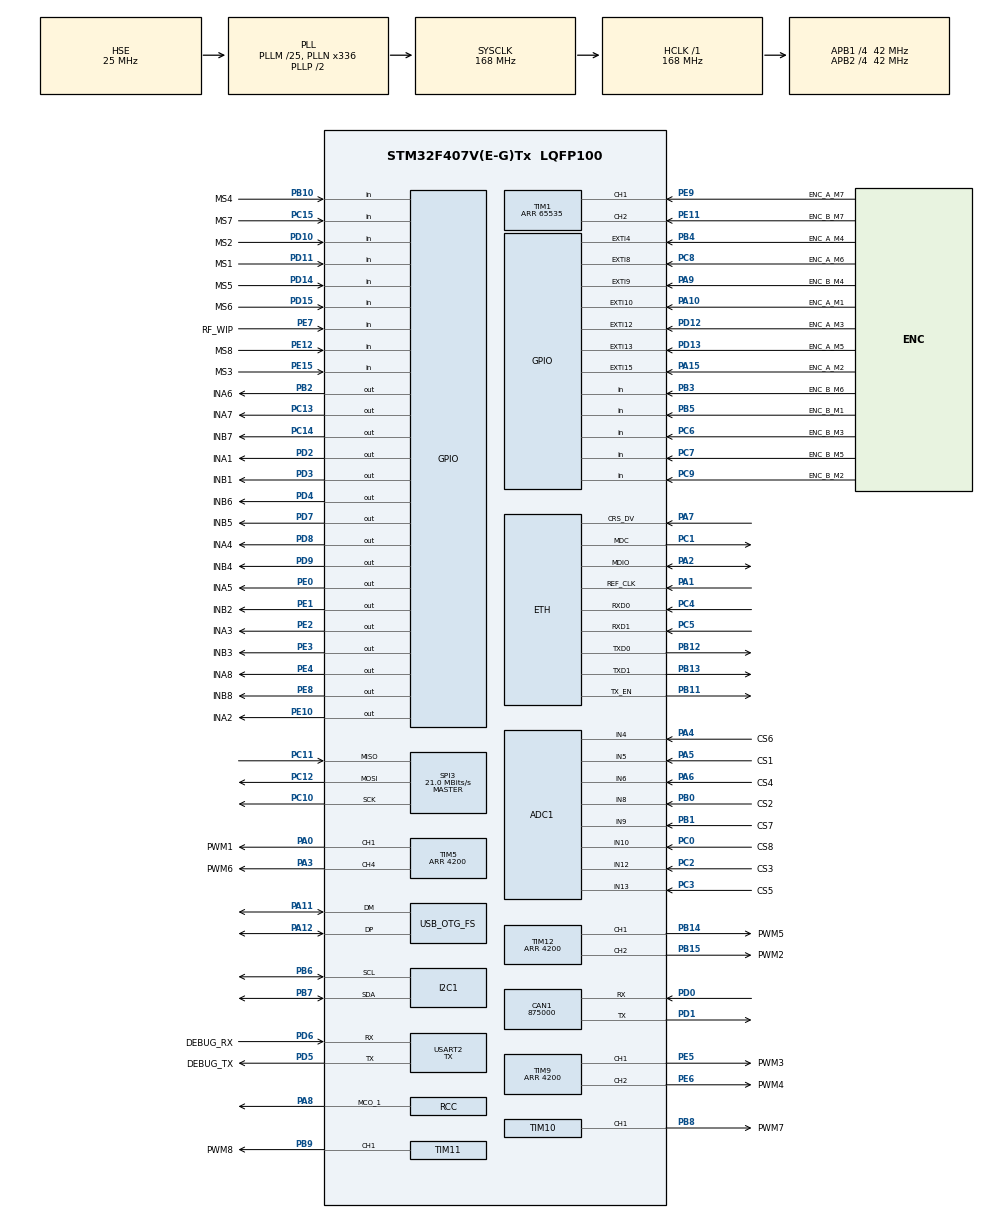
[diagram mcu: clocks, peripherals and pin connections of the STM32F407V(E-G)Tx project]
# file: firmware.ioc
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ADC1.Channel-0\#ChannelRegularConversion=ADC_CHANNEL_4
ADC1.ClockPrescaler=ADC_CLOCK_SYNC_PCLK_DIV4
ADC1.NbrOfConversionFlag=1
ADC1.Rank-0\#ChannelRegularConversion=1
ADC1.SamplingTime-0\#ChannelRegularConversion=ADC_SAMPLETIME_3CYCLES
ADC1.master=1
ADC2.Channel-0\#ChannelRegularConversion=ADC_CHANNEL_4
ADC2.ClockPrescaler=ADC_CLOCK_SYNC_PCLK_DIV4
ADC2.NbrOfConversionFlag=1
ADC2.Rank-0\#ChannelRegularConversion=1
ADC2.SamplingTime-0\#ChannelRegularConversion=ADC_SAMPLETIME_3CYCLES
ADC3.Channel-0\#ChannelRegularConversion=ADC_CHANNEL_10
ADC3.ClockPrescaler=ADC_CLOCK_SYNC_PCLK_DIV4
ADC3.NbrOfConversionFlag=1
ADC3.Rank-0\#ChannelRegularConversion=1
ADC3.SamplingTime-0\#ChannelRegularConversion=ADC_SAMPLETIME_3CYCLES
CAN1.BS1=CAN_BS1_1TQ
CAN1.BS2=CAN_BS2_1TQ
CAN1.CalculateBaudRate=875000
CAN1.CalculateTimeBit=1142
CAN1.CalculateTimeQuantum=380.95238095238096
ETH.ChecksumMode=ETH_CHECKSUM_BY_HARDWARE
ETH.MediaInterface=HAL_ETH_RMII_MODE
ETH.PHY_DUPLEX_STATUS=0x0010
ETH.PHY_Name_RMII=userPHY
ETH.PHY_SPEED_STATUS=0x0004
ETH.PHY_SR=31
ETH.PHY_User_Name=LAN8720A
ETH.PhyAddress=0
FREERTOS.Tasks01=defaultTask,0,256,StartDefaultTask,Default,NULL,Dynamic,NULL,NULL
FREERTOS.configENABLE_FPU=0
FREERTOS.configGENERATE_RUN_TIME_STATS=1
FREERTOS.configTOTAL_HEAP_SIZE=32360
FREERTOS.configUSE_STATS_FORMATTING_FUNCTIONS=1
FREERTOS.configUSE_TRACE_FACILITY=1
LWIP.API_LIB_DEBUG=LWIP_DBG_ON
LWIP.API_MSG_DEBUG=LWIP_DBG_ON
LWIP.BSP.number=1
LWIP.DHCP_DEBUG=LWIP_DBG_ON
LWIP.ETHARP_DEBUG=LWIP_DBG_ON
LWIP.GATEWAY_ADDRESS=010.000.000.001
LWIP.ICMP_DEBUG=LWIP_DBG_ON
LWIP.IGMP_DEBUG=LWIP_DBG_ON
LWIP.INET_DEBUG=LWIP_DBG_ON
LWIP.IP_ADDRESS=010.000.000.002
LWIP.IP_DEBUG=LWIP_DBG_ON
LWIP.IP_REASS_DEBUG=LWIP_DBG_OFF
LWIP.LWIP_DBG_MIN_LEVEL=LWIP_DBG_LEVEL_WARNING
LWIP.LWIP_DHCP=1
LWIP.LWIP_DNS=1
LWIP.LWIP_IGMP=1
LWIP.LWIP_MDNS=1
LWIP.LWIP_MDNS_RESPONDER=1
LWIP.LWIP_RAM_HEAP_POINTER=0x30044000
LWIP.LWIP_SNTP=1
LWIP.MDNS_MAX_SERVICES=2
LWIP.MEMP_MEM_INIT=0
LWIP.MEMP_MEM_MALLOC=0
LWIP.MEMP_NUM_TCP_PCB=10
LWIP.NETIF_DEBUG=LWIP_DBG_ON
LWIP.NETMASK_ADDRESS=255.255.255.000
LWIP.PBUF_DEBUG=LWIP_DBG_ON
LWIP.RAW_DEBUG=LWIP_DBG_ON
LWIP.SOCKETS_DEBUG=LWIP_DBG_ON
LWIP.TCPIP_DEBUG=LWIP_DBG_ON
LWIP.TCP_DEBUG=LWIP_DBG_ON
LWIP.TCP_INPUT_DEBUG=LWIP_DBG_ON
LWIP.Version=v2.1.2_Cube
LWIP0.BSP.STBoard=false
LWIP0.BSP.api=BSP_COMPONENT_DRIVER
LWIP0.BSP.component=LAN8742
LWIP0.BSP.i2caddr=0
LWIP0.BSP.instance=LAN8742
LWIP0.BSP.name=Driver_PHY
LWIP0.BSP.semaphore=S_LAN8742
LWIP0.BSP.solution=LAN8742
MBEDTLS.MBEDTLS_RNG_IP=SW_RNG
Mcu.Family=STM32F4
Mcu.Name=STM32F407V(E-G)Tx
Mcu.Package=LQFP100
NVIC.ETH_IRQn=true\:5\:0\:false\:false\:true\:true\:false\:true\:true
NVIC.EXTI15_10_IRQn=true\:5\:0\:false\:false\:true\:true\:true\:true\:true
NVIC.EXTI4_IRQn=true\:5\:0\:false\:false\:true\:true\:true\:true\:true
NVIC.EXTI9_5_IRQn=true\:5\:0\:false\:false\:true\:true\:true\:true\:true
NVIC.OTG_FS_IRQn=true\:5\:0\:false\:false\:true\:true\:false\:true\:true
NVIC.PriorityGroup=NVIC_PRIORITYGROUP_4
NVIC.TIM6_DAC_IRQn=true\:5\:0\:false\:false\:true\:true\:true\:true\:true
PA0-WKUP.GPIO_Label=PWM1
PA0-WKUP.Signal=S_TIM5_CH1
PA1.Mode=RMII
PA1.Signal=ETH_REF_CLK
PA10.GPIO_Label=ENC_A_M1
PA10.GPIO_ModeDefaultEXTI=GPIO_MODE_IT_RISING_FALLING
PA10.GPIO_PuPd=GPIO_PULLUP
PA10.Signal=GPXTI10
PA11.Mode=Device_Only
PA11.Signal=USB_OTG_FS_DM
PA12.Mode=Device_Only
PA12.Signal=USB_OTG_FS_DP
PA13.Mode=Serial_Wire
PA13.Signal=SYS_JTMS-SWDIO
PA14.Mode=Serial_Wire
PA14.Signal=SYS_JTCK-SWCLK
PA15.GPIO_Label=ENC_A_M2
PA15.GPIO_ModeDefaultEXTI=GPIO_MODE_IT_RISING_FALLING
PA15.GPIO_PuPd=GPIO_PULLUP
PA15.Signal=GPXTI15
PA2.Mode=RMII
PA2.Signal=ETH_MDIO
PA3.GPIO_Label=PWM6
PA3.Signal=S_TIM5_CH4
PA4.GPIO_Label=CS6
PA4.Signal=ADCx_IN4
PA5.GPIO_Label=CS1
PA5.Signal=ADCx_IN5
PA6.GPIO_Label=CS4
PA6.Signal=ADCx_IN6
PA7.Mode=RMII
PA7.Signal=ETH_CRS_DV
PA8.Mode=Clock-out-1
PA8.Signal=RCC_MCO_1
PA9.GPIO_Label=ENC_B_M4
PA9.GPIO_ModeDefaultEXTI=GPIO_MODE_IT_RISING_FALLING
PA9.GPIO_PuPd=GPIO_PULLUP
PA9.Signal=GPXTI9
PB0.GPIO_Label=CS2
PB0.Signal=ADCx_IN8
PB1.GPIO_Label=CS7
PB1.Signal=ADCx_IN9
PB10.GPIO_Label=MS4
PB10.GPIO_PuPd=GPIO_PULLUP
PB10.Signal=GPIO_Input
PB11.Mode=RMII
PB11.Signal=ETH_TX_EN
PB12.Mode=RMII
PB12.Signal=ETH_TXD0
PB13.Mode=RMII
PB13.Signal=ETH_TXD1
PB14.GPIO_Label=PWM5
PB14.Signal=S_TIM12_CH1
PB15.GPIO_Label=PWM2
PB15.Signal=S_TIM12_CH2
PB2.GPIO_Label=INA6
PB2.Signal=GPIO_Output
PB3.GPIO_Label=ENC_B_M6
PB3.GPIO_PuPd=GPIO_PULLUP
PB3.Signal=GPIO_Input
PB4.GPIO_Label=ENC_A_M4
PB4.GPIO_ModeDefaultEXTI=GPIO_MODE_IT_RISING_FALLING
PB4.GPIO_PuPd=GPIO_PULLUP
PB4.Signal=GPXTI4
PB5.GPIO_Label=ENC_B_M1
PB5.GPIO_PuPd=GPIO_PULLUP
PB5.Signal=GPIO_Input
PB6.GPIO_Pu=GPIO_PULLUP
PB6.Mode=I2C
PB6.Signal=I2C1_SCL
PB7.GPIO_Pu=GPIO_PULLUP
PB7.Mode=I2C
PB7.Signal=I2C1_SDA
PB8.GPIO_Label=PWM7
PB8.Signal=S_TIM10_CH1
PB9.GPIO_Label=PWM8
PB9.Signal=S_TIM11_CH1
PC0.GPIO_Label=CS8
PC0.Signal=ADCx_IN10
PC1.Mode=RMII
PC1.Signal=ETH_MDC
PC10.Mode=Full_Duplex_Master
PC10.Signal=SPI3_SCK
PC11.Mode=Full_Duplex_Master
PC11.Signal=SPI3_MISO
PC12.Mode=Full_Duplex_Master
PC12.Signal=SPI3_MOSI
PC13-ANTI_TAMP.GPIO_Label=INA7
PC13-ANTI_TAMP.Signal=GPIO_Output
PC14-OSC32_IN.GPIO_Label=INB7
PC14-OSC32_IN.Signal=GPIO_Output
PC15-OSC32_OUT.GPIO_Label=MS7
PC15-OSC32_OUT.GPIO_PuPd=GPIO_PULLUP
PC15-OSC32_OUT.Signal=GPIO_Input
PC2.GPIO_Label=CS3
PC2.Signal=ADCx_IN12
PC3.GPIO_Label=CS5
PC3.Signal=ADCx_IN13
PC4.Mode=RMII
PC4.Signal=ETH_RXD0
PC5.Mode=RMII
PC5.Signal=ETH_RXD1
PC6.GPIO_Label=ENC_B_M3
PC6.GPIO_PuPd=GPIO_PULLUP
PC6.Signal=GPIO_Input
PC7.GPIO_Label=ENC_B_M5
PC7.GPIO_PuPd=GPIO_PULLUP
PC7.Signal=GPIO_Input
PC8.GPIO_Label=ENC_A_M6
PC8.GPIO_ModeDefaultEXTI=GPIO_MODE_IT_RISING_FALLING
PC8.GPIO_PuPd=GPIO_PULLUP
PC8.Signal=GPXTI8
PC9.GPIO_Label=ENC_B_M2
PC9.GPIO_PuPd=GPIO_PULLUP
PC9.Signal=GPIO_Input
PD0.Mode=CAN_Activate
PD0.Signal=CAN1_RX
PD1.Mode=CAN_Activate
PD1.Signal=CAN1_TX
PD10.GPIO_Label=MS2
PD10.GPIO_PuPd=GPIO_PULLUP
PD10.Signal=GPIO_Input
PD11.GPIO_Label=MS1
PD11.GPIO_PuPd=GPIO_PULLUP
PD11.Signal=GPIO_Input
PD12.GPIO_Label=ENC_A_M3
PD12.GPIO_ModeDefaultEXTI=GPIO_MODE_IT_RISING_FALLING
PD12.GPIO_PuPd=GPIO_PULLUP
PD12.Signal=GPXTI12
PD13.GPIO_Label=ENC_A_M5
PD13.GPIO_ModeDefaultEXTI=GPIO_MODE_IT_RISING_FALLING
PD13.GPIO_PuPd=GPIO_PULLUP
PD13.Signal=GPXTI13
PD14.GPIO_Label=MS5
PD14.GPIO_PuPd=GPIO_PULLUP
PD14.Signal=GPIO_Input
PD15.GPIO_Label=MS6
PD15.GPIO_PuPd=GPIO_PULLUP
PD15.Signal=GPIO_Input
PD2.GPIO_Label=INA1
PD2.Signal=GPIO_Output
PD3.GPIO_Label=INB1
PD3.Signal=GPIO_Output
PD4.GPIO_Label=INB6
PD4.Signal=GPIO_Output
PD5.GPIO_Label=DEBUG_TX
PD5.Mode=Asynchronous
PD5.Signal=USART2_TX
PD6.GPIO_Label=DEBUG_RX
PD6.Mode=Asynchronous
PD6.Signal=USART2_RX
PD7.GPIO_Label=INB5
PD7.Signal=GPIO_Output
PD8.GPIO_Label=INA4
PD8.Signal=GPIO_Output
PD9.GPIO_Label=INB4
PD9.Signal=GPIO_Output
PE0.GPIO_Label=INA5
PE0.Signal=GPIO_Output
PE1.GPIO_Label=INB2
PE1.Signal=GPIO_Output
PE10.GPIO_Label=INA2
PE10.Signal=GPIO_Output
PE11.GPIO_Label=ENC_B_M7
PE11.Signal=S_TIM1_CH2
PE12.GPIO_Label=MS8
PE12.GPIO_PuPd=GPIO_PULLUP
PE12.Signal=GPIO_Input
PE15.GPIO_Label=MS3
PE15.GPIO_PuPd=GPIO_PULLUP
PE15.Signal=GPIO_Input
PE2.GPIO_Label=INA3
PE2.Signal=GPIO_Output
PE3.GPIO_Label=INB3
PE3.Signal=GPIO_Output
PE4.GPIO_Label=INA8
PE4.Signal=GPIO_Output
PE5.GPIO_Label=PWM3
PE5.Signal=S_TIM9_CH1
PE6.GPIO_Label=PWM4
PE6.Signal=S_TIM9_CH2
PE7.GPIO_Label=RF_WIP
PE7.Signal=GPIO_Input
PE8.GPIO_Label=INB8
PE8.Signal=GPIO_Output
PE9.GPIO_Label=ENC_A_M7
PE9.Signal=S_TIM1_CH1
PH0-OSC_IN.Mode=HSE-External-Oscillator
PH0-OSC_IN.Signal=RCC_OSC_IN
PH1-OSC_OUT.Mode=HSE-External-Oscillator
PH1-OSC_OUT.Signal=RCC_OSC_OUT
ProjectManager.HeapSize=0x400
ProjectManager.StackSize=0x600
ProjectManager.TargetToolchain=Makefile
RCC.48MHZClocksFreq_Value=48000000
RCC.AHBFreq_Value=168000000
RCC.APB1CLKDivider=RCC_HCLK_DIV4
RCC.APB1Freq_Value=42000000
RCC.APB1TimFreq_Value=84000000
RCC.APB2CLKDivider=RCC_HCLK_DIV4
RCC.APB2Freq_Value=42000000
RCC.APB2TimFreq_Value=84000000
RCC.CortexFreq_Value=168000000
RCC.HCLKFreq_Value=168000000
RCC.HSE_VALUE=25000000
RCC.HSI_VALUE=16000000
RCC.LSE_VALUE=32768
RCC.PLLM=25
RCC.PLLN=336
RCC.PLLQ=7
RCC.RCC_MCO1Source=RCC_MCO1SOURCE_HSE
RCC.SYSCLKFreq_VALUE=168000000
RCC.SYSCLKSource=RCC_SYSCLKSOURCE_PLLCLK
RCC.VCOOutputFreq_Value=336000000
SH.ADCx_IN10.0=ADC1_IN10,IN10
SH.ADCx_IN10.1=ADC2_IN10,IN10
SH.ADCx_IN10.2=ADC3_IN10,IN10
SH.ADCx_IN12.0=ADC1_IN12,IN12
SH.ADCx_IN12.1=ADC2_IN12,IN12
SH.ADCx_IN12.2=ADC3_IN12,IN12
SH.ADCx_IN13.0=ADC1_IN13,IN13
SH.ADCx_IN13.1=ADC2_IN13,IN13
SH.ADCx_IN13.2=ADC3_IN13,IN13
SH.ADCx_IN4.0=ADC1_IN4,IN4
SH.ADCx_IN4.1=ADC2_IN4,IN4
SH.ADCx_IN5.0=ADC1_IN5,IN5
SH.ADCx_IN5.1=ADC2_IN5,IN5
SH.ADCx_IN6.0=ADC1_IN6,IN6
SH.ADCx_IN6.1=ADC2_IN6,IN6
SH.ADCx_IN8.0=ADC1_IN8,IN8
SH.ADCx_IN8.1=ADC2_IN8,IN8
SH.ADCx_IN9.0=ADC1_IN9,IN9
SH.ADCx_IN9.1=ADC2_IN9,IN9
SH.S_TIM10_CH1.0=TIM10_CH1,PWM Generation1 CH1
SH.S_TIM11_CH1.0=TIM11_CH1,PWM Generation1 CH1
SH.S_TIM12_CH1.0=TIM12_CH1,PWM Generation1 CH1
SH.S_TIM12_CH2.0=TIM12_CH2,PWM Generation2 CH2
SH.S_TIM1_CH1.0=TIM1_CH1,Encoder_Interface
SH.S_TIM1_CH2.0=TIM1_CH2,Encoder_Interface
SH.S_TIM5_CH1.0=TIM5_CH1,PWM Generation1 CH1
SH.S_TIM5_CH4.0=TIM5_CH4,PWM Generation4 CH4
SH.S_TIM9_CH1.0=TIM9_CH1,PWM Generation1 CH1
SH.S_TIM9_CH2.0=TIM9_CH2,PWM Generation2 CH2
SPI3.BaudRatePrescaler=SPI_BAUDRATEPRESCALER_2
SPI3.CalculateBaudRate=21.0 MBits/s
SPI3.Direction=SPI_DIRECTION_2LINES
SPI3.Mode=SPI_MODE_MASTER
SPI3.VirtualType=VM_MASTER
TIM1.Period=65535
TIM10.Channel=TIM_CHANNEL_1
TIM10.Period=4200
TIM10.Prescaler=0
TIM10.Pulse=0
TIM11.Channel=TIM_CHANNEL_1
TIM11.Period=4200
TIM12.Channel-PWM\ Generation1\ CH1=TIM_CHANNEL_1
TIM12.Channel-PWM\ Generation2\ CH2=TIM_CHANNEL_2
TIM12.Period=4200
TIM5.Channel-PWM\ Generation1\ CH1=TIM_CHANNEL_1
TIM5.Channel-PWM\ Generation4\ CH4=TIM_CHANNEL_4
TIM5.Period=4200
TIM6.Period=1
TIM6.Prescaler=8399
TIM6.TIM_MasterOutputTrigger=TIM_TRGO_UPDATE
TIM9.Channel-PWM\ Generation1\ CH1=TIM_CHANNEL_1
TIM9.Channel-PWM\ Generation2\ CH2=TIM_CHANNEL_2
TIM9.Period=4200
USART2.Mode=MODE_TX
USART2.VirtualMode=VM_ASYNC
USB_DEVICE.CLASS_NAME_FS=HID
USB_DEVICE.VirtualMode-HID_FS=Hid
USB_DEVICE.VirtualModeFS=Hid_FS
USB_OTG_FS.VirtualMode=Device_Only
VP_FREERTOS_VS_CMSIS_V1.Mode=CMSIS_V1
VP_LWIP_VS_Enabled.Mode=Enabled
VP_MBEDTLS_VS_MBEDTLS.Mode=Enabled
VP_TIM10_VS_ClockSourceINT.Mode=Enable_Timer
VP_TIM11_VS_ClockSourceINT.Mode=Enable_Timer
VP_TIM6_VS_ClockSourceINT.Mode=Enable_Timer
VP_USB_DEVICE_VS_USB_DEVICE_HID_FS.Mode=HID_FS
board=firmware

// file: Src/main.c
/* USER CODE BEGIN Header */
/**
  ******************************************************************************
  * @file           : main.c
  * @brief          : Main program body
  ******************************************************************************
  * @attention
  *
  * Copyright (c) 2025 STMicroelectronics.
  * All rights reserved.
  *
  * This software is licensed under terms that can be found in the LICENSE file
  * in the root directory of this software component.
  * If no LICENSE file comes with this software, it is provided AS-IS.
  *
  ******************************************************************************
  */
/* USER CODE END Header */
#include "main.h"
#include "cmsis_os.h"
#include "mbedtls.h"
#include "usb_device.h"

/* USER CODE BEGIN Includes */
#include "lwip.h"
#include "scorbot.h"
#include "motor.h"

/* USER CODE END Includes */

 ADC_HandleTypeDef hadc1;
ADC_HandleTypeDef hadc2;
ADC_HandleTypeDef hadc3;

CAN_HandleTypeDef hcan1;

I2C_HandleTypeDef hi2c1;

SPI_HandleTypeDef hspi3;

TIM_HandleTypeDef htim1;
TIM_HandleTypeDef htim5;
TIM_HandleTypeDef htim6;
TIM_HandleTypeDef htim9;
TIM_HandleTypeDef htim10;
TIM_HandleTypeDef htim11;
TIM_HandleTypeDef htim12;

UART_HandleTypeDef huart2;

osThreadId defaultTaskHandle;
/* USER CODE BEGIN PV */
/* Private variables ---------------------------------------------------------*/

/* USER CODE END PV */

void SystemClock_Config(void);
static void MX_GPIO_Init(void);
static void MX_ADC1_Init(void);
static void MX_ADC2_Init(void);
static void MX_ADC3_Init(void);
static void MX_CAN1_Init(void);
static void MX_I2C1_Init(void);
static void MX_SPI3_Init(void);
static void MX_TIM1_Init(void);
static void MX_TIM5_Init(void);
static void MX_TIM6_Init(void);
static void MX_TIM9_Init(void);
static void MX_TIM10_Init(void);
static void MX_TIM11_Init(void);
static void MX_TIM12_Init(void);
static void MX_USART2_UART_Init(void);
void StartDefaultTask(void const * argument);

/* USER CODE BEGIN PFP */
/* Private function prototypes -----------------------------------------------*/

/* USER CODE END PFP */

/* USER CODE BEGIN 0 */
#define DHCP_START                 1
#define DHCP_WAIT_ADDRESS          2
#define DHCP_ADDRESS_ASSIGNED      3
#define DHCP_TIMEOUT               4
#define DHCP_LINK_DOWN             5

#define DHCP_TASK_PRIO   ( tskIDLE_PRIORITY + 4 )

uint8_t DHCP_state;

/* Retarget printf to UART2 */
int _write(int file, char *ptr, int len)
{
    HAL_UART_Transmit(&huart2, (uint8_t *)ptr, len, HAL_MAX_DELAY);
    return len;
}
/* USER CODE END 0 */

int main(void)
{

  /* MCU Configuration--------------------------------------------------------*/

  /* Reset of all peripherals, Initializes the Flash interface and the Systick. */
  HAL_Init();

  /* Configure the system clock */
  SystemClock_Config();

  /* USER CODE BEGIN SysInit */
  __HAL_RCC_GPIOB_CLK_ENABLE();

  /*Configure GPIO pin Output Level */
  HAL_GPIO_WritePin(GPIOB, GPIO_PIN_6, 0);

  GPIO_InitTypeDef GPIO_InitStruct;

  GPIO_InitStruct.Pin = GPIO_PIN_6;
  GPIO_InitStruct.Mode = GPIO_MODE_OUTPUT_PP;
  GPIO_InitStruct.Pull = GPIO_NOPULL;
  GPIO_InitStruct.Speed = GPIO_SPEED_FREQ_LOW;
  HAL_GPIO_Init(GPIOB, &GPIO_InitStruct);
  HAL_Delay(1);
  HAL_GPIO_WritePin(GPIOB, GPIO_PIN_6, 1);
  HAL_Delay(1);
  /* USER CODE END SysInit */

  /* Initialize all configured peripherals */
  MX_GPIO_Init();
  MX_ADC1_Init();
  MX_ADC2_Init();
  MX_ADC3_Init();
  MX_CAN1_Init();
  MX_I2C1_Init();
  MX_SPI3_Init();
  MX_TIM1_Init();
  MX_TIM5_Init();
  MX_TIM6_Init();
  MX_TIM9_Init();
  MX_TIM10_Init();
  MX_TIM11_Init();
  MX_TIM12_Init();
  MX_USART2_UART_Init();
  MX_MBEDTLS_Init();
  /* USER CODE BEGIN 2 */
  printf("Starting...\r\n");
  motor_init();

//  TIM10->ARR = 12000;
//  HAL_TIM_Base_Start_IT(&htim6); // motor interrupt loop
//  INA7_GPIO_Port->ODR |= INA7_Pin;
//  TIM10->CCR1 = 0xffff;

  /* USER CODE END 2 */

  /* Create the thread(s) */
  /* definition and creation of defaultTask */
  osThreadDef(defaultTask, StartDefaultTask, osPriorityNormal, 0, 256);
  defaultTaskHandle = osThreadCreate(osThread(defaultTask), NULL);

  /* Start scheduler */
  osKernelStart();

  /* We should never get here as control is now taken by the scheduler */
  /* Infinite loop */
  while (1)
  {

  }
}

void SystemClock_Config(void)
{
  RCC_OscInitTypeDef RCC_OscInitStruct = {0};
  RCC_ClkInitTypeDef RCC_ClkInitStruct = {0};

  /** Configure the main internal regulator output voltage
  */
  __HAL_RCC_PWR_CLK_ENABLE();
  __HAL_PWR_VOLTAGESCALING_CONFIG(PWR_REGULATOR_VOLTAGE_SCALE1);

  /** Initializes the RCC Oscillators according to the specified parameters
  * in the RCC_OscInitTypeDef structure.
  */
  RCC_OscInitStruct.OscillatorType = RCC_OSCILLATORTYPE_HSE;
  RCC_OscInitStruct.HSEState = RCC_HSE_ON;
  RCC_OscInitStruct.PLL.PLLState = RCC_PLL_ON;
  RCC_OscInitStruct.PLL.PLLSource = RCC_PLLSOURCE_HSE;
  RCC_OscInitStruct.PLL.PLLM = 25;
  RCC_OscInitStruct.PLL.PLLN = 336;
  RCC_OscInitStruct.PLL.PLLP = RCC_PLLP_DIV2;
  RCC_OscInitStruct.PLL.PLLQ = 7;
  if (HAL_RCC_OscConfig(&RCC_OscInitStruct) != HAL_OK)
  {
    Error_Handler();
  }

  /** Initializes the CPU, AHB and APB buses clocks
  */
  RCC_ClkInitStruct.ClockType = RCC_CLOCKTYPE_HCLK|RCC_CLOCKTYPE_SYSCLK
                              |RCC_CLOCKTYPE_PCLK1|RCC_CLOCKTYPE_PCLK2;
  RCC_ClkInitStruct.SYSCLKSource = RCC_SYSCLKSOURCE_PLLCLK;
  RCC_ClkInitStruct.AHBCLKDivider = RCC_SYSCLK_DIV1;
  RCC_ClkInitStruct.APB1CLKDivider = RCC_HCLK_DIV4;
  RCC_ClkInitStruct.APB2CLKDivider = RCC_HCLK_DIV4;

  if (HAL_RCC_ClockConfig(&RCC_ClkInitStruct, FLASH_LATENCY_5) != HAL_OK)
  {
    Error_Handler();
  }
  HAL_RCC_MCOConfig(RCC_MCO1, RCC_MCO1SOURCE_HSE, RCC_MCODIV_1);
}

static void MX_ADC1_Init(void)
{

  ADC_ChannelConfTypeDef sConfig = {0};

  /** Configure the global features of the ADC (Clock, Resolution, Data Alignment and number of conversion)
  */
  hadc1.Instance = ADC1;
  hadc1.Init.ClockPrescaler = ADC_CLOCK_SYNC_PCLK_DIV4;
  hadc1.Init.Resolution = ADC_RESOLUTION_12B;
  hadc1.Init.ScanConvMode = DISABLE;
  hadc1.Init.ContinuousConvMode = DISABLE;
  hadc1.Init.DiscontinuousConvMode = DISABLE;
  hadc1.Init.ExternalTrigConvEdge = ADC_EXTERNALTRIGCONVEDGE_NONE;
  hadc1.Init.ExternalTrigConv = ADC_SOFTWARE_START;
  hadc1.Init.DataAlign = ADC_DATAALIGN_RIGHT;
  hadc1.Init.NbrOfConversion = 1;
  hadc1.Init.DMAContinuousRequests = DISABLE;
  hadc1.Init.EOCSelection = ADC_EOC_SINGLE_CONV;
  if (HAL_ADC_Init(&hadc1) != HAL_OK)
  {
    Error_Handler();
  }

  /** Configure for the selected ADC regular channel its corresponding rank in the sequencer and its sample time.
  */
  sConfig.Channel = ADC_CHANNEL_4;
  sConfig.Rank = 1;
  sConfig.SamplingTime = ADC_SAMPLETIME_3CYCLES;
  if (HAL_ADC_ConfigChannel(&hadc1, &sConfig) != HAL_OK)
  {
    Error_Handler();
  }

}

static void MX_ADC2_Init(void)
{

  ADC_ChannelConfTypeDef sConfig = {0};

  /** Configure the global features of the ADC (Clock, Resolution, Data Alignment and number of conversion)
  */
  hadc2.Instance = ADC2;
  hadc2.Init.ClockPrescaler = ADC_CLOCK_SYNC_PCLK_DIV4;
  hadc2.Init.Resolution = ADC_RESOLUTION_12B;
  hadc2.Init.ScanConvMode = DISABLE;
  hadc2.Init.ContinuousConvMode = DISABLE;
  hadc2.Init.DiscontinuousConvMode = DISABLE;
  hadc2.Init.ExternalTrigConvEdge = ADC_EXTERNALTRIGCONVEDGE_NONE;
  hadc2.Init.ExternalTrigConv = ADC_SOFTWARE_START;
  hadc2.Init.DataAlign = ADC_DATAALIGN_RIGHT;
  hadc2.Init.NbrOfConversion = 1;
  hadc2.Init.DMAContinuousRequests = DISABLE;
  hadc2.Init.EOCSelection = ADC_EOC_SINGLE_CONV;
  if (HAL_ADC_Init(&hadc2) != HAL_OK)
  {
    Error_Handler();
  }

  /** Configure for the selected ADC regular channel its corresponding rank in the sequencer and its sample time.
  */
  sConfig.Channel = ADC_CHANNEL_4;
  sConfig.Rank = 1;
  sConfig.SamplingTime = ADC_SAMPLETIME_3CYCLES;
  if (HAL_ADC_ConfigChannel(&hadc2, &sConfig) != HAL_OK)
  {
    Error_Handler();
  }

}

static void MX_ADC3_Init(void)
{

  ADC_ChannelConfTypeDef sConfig = {0};

  /** Configure the global features of the ADC (Clock, Resolution, Data Alignment and number of conversion)
  */
  hadc3.Instance = ADC3;
  hadc3.Init.ClockPrescaler = ADC_CLOCK_SYNC_PCLK_DIV4;
  hadc3.Init.Resolution = ADC_RESOLUTION_12B;
  hadc3.Init.ScanConvMode = DISABLE;
  hadc3.Init.ContinuousConvMode = DISABLE;
  hadc3.Init.DiscontinuousConvMode = DISABLE;
  hadc3.Init.ExternalTrigConvEdge = ADC_EXTERNALTRIGCONVEDGE_NONE;
  hadc3.Init.ExternalTrigConv = ADC_SOFTWARE_START;
  hadc3.Init.DataAlign = ADC_DATAALIGN_RIGHT;
  hadc3.Init.NbrOfConversion = 1;
  hadc3.Init.DMAContinuousRequests = DISABLE;
  hadc3.Init.EOCSelection = ADC_EOC_SINGLE_CONV;
  if (HAL_ADC_Init(&hadc3) != HAL_OK)
  {
    Error_Handler();
  }

  /** Configure for the selected ADC regular channel its corresponding rank in the sequencer and its sample time.
  */
  sConfig.Channel = ADC_CHANNEL_10;
  sConfig.Rank = 1;
  sConfig.SamplingTime = ADC_SAMPLETIME_3CYCLES;
  if (HAL_ADC_ConfigChannel(&hadc3, &sConfig) != HAL_OK)
  {
    Error_Handler();
  }

}

static void MX_CAN1_Init(void)
{

  hcan1.Instance = CAN1;
  hcan1.Init.Prescaler = 16;
  hcan1.Init.Mode = CAN_MODE_NORMAL;
  hcan1.Init.SyncJumpWidth = CAN_SJW_1TQ;
  hcan1.Init.TimeSeg1 = CAN_BS1_1TQ;
  hcan1.Init.TimeSeg2 = CAN_BS2_1TQ;
  hcan1.Init.TimeTriggeredMode = DISABLE;
  hcan1.Init.AutoBusOff = DISABLE;
  hcan1.Init.AutoWakeUp = DISABLE;
  hcan1.Init.AutoRetransmission = DISABLE;
  hcan1.Init.ReceiveFifoLocked = DISABLE;
  hcan1.Init.TransmitFifoPriority = DISABLE;
  if (HAL_CAN_Init(&hcan1) != HAL_OK)
  {
    Error_Handler();
  }

}

static void MX_I2C1_Init(void)
{

  hi2c1.Instance = I2C1;
  hi2c1.Init.ClockSpeed = 100000;
  hi2c1.Init.DutyCycle = I2C_DUTYCYCLE_2;
  hi2c1.Init.OwnAddress1 = 0;
  hi2c1.Init.AddressingMode = I2C_ADDRESSINGMODE_7BIT;
  hi2c1.Init.DualAddressMode = I2C_DUALADDRESS_DISABLE;
  hi2c1.Init.OwnAddress2 = 0;
  hi2c1.Init.GeneralCallMode = I2C_GENERALCALL_DISABLE;
  hi2c1.Init.NoStretchMode = I2C_NOSTRETCH_DISABLE;
  if (HAL_I2C_Init(&hi2c1) != HAL_OK)
  {
    Error_Handler();
  }

}

static void MX_SPI3_Init(void)
{

  /* SPI3 parameter configuration*/
  hspi3.Instance = SPI3;
  hspi3.Init.Mode = SPI_MODE_MASTER;
  hspi3.Init.Direction = SPI_DIRECTION_2LINES;
  hspi3.Init.DataSize = SPI_DATASIZE_8BIT;
  hspi3.Init.CLKPolarity = SPI_POLARITY_LOW;
  hspi3.Init.CLKPhase = SPI_PHASE_1EDGE;
  hspi3.Init.NSS = SPI_NSS_SOFT;
  hspi3.Init.BaudRatePrescaler = SPI_BAUDRATEPRESCALER_2;
  hspi3.Init.FirstBit = SPI_FIRSTBIT_MSB;
  hspi3.Init.TIMode = SPI_TIMODE_DISABLE;
  hspi3.Init.CRCCalculation = SPI_CRCCALCULATION_DISABLE;
  hspi3.Init.CRCPolynomial = 10;
  if (HAL_SPI_Init(&hspi3) != HAL_OK)
  {
    Error_Handler();
  }

}

static void MX_TIM1_Init(void)
{

  TIM_Encoder_InitTypeDef sConfig = {0};
  TIM_MasterConfigTypeDef sMasterConfig = {0};

  htim1.Instance = TIM1;
  htim1.Init.Prescaler = 0;
  htim1.Init.CounterMode = TIM_COUNTERMODE_UP;
  htim1.Init.Period = 65535;
  htim1.Init.ClockDivision = TIM_CLOCKDIVISION_DIV1;
  htim1.Init.RepetitionCounter = 0;
  htim1.Init.AutoReloadPreload = TIM_AUTORELOAD_PRELOAD_DISABLE;
  sConfig.EncoderMode = TIM_ENCODERMODE_TI1;
  sConfig.IC1Polarity = TIM_ICPOLARITY_RISING;
  sConfig.IC1Selection = TIM_ICSELECTION_DIRECTTI;
  sConfig.IC1Prescaler = TIM_ICPSC_DIV1;
  sConfig.IC1Filter = 0;
  sConfig.IC2Polarity = TIM_ICPOLARITY_RISING;
  sConfig.IC2Selection = TIM_ICSELECTION_DIRECTTI;
  sConfig.IC2Prescaler = TIM_ICPSC_DIV1;
  sConfig.IC2Filter = 0;
  if (HAL_TIM_Encoder_Init(&htim1, &sConfig) != HAL_OK)
  {
    Error_Handler();
  }
  sMasterConfig.MasterOutputTrigger = TIM_TRGO_RESET;
  sMasterConfig.MasterSlaveMode = TIM_MASTERSLAVEMODE_DISABLE;
  if (HAL_TIMEx_MasterConfigSynchronization(&htim1, &sMasterConfig) != HAL_OK)
  {
    Error_Handler();
  }

}

static void MX_TIM5_Init(void)
{

  TIM_MasterConfigTypeDef sMasterConfig = {0};
  TIM_OC_InitTypeDef sConfigOC = {0};

  htim5.Instance = TIM5;
  htim5.Init.Prescaler = 0;
  htim5.Init.CounterMode = TIM_COUNTERMODE_UP;
  htim5.Init.Period = 4200;
  htim5.Init.ClockDivision = TIM_CLOCKDIVISION_DIV1;
  htim5.Init.AutoReloadPreload = TIM_AUTORELOAD_PRELOAD_DISABLE;
  if (HAL_TIM_PWM_Init(&htim5) != HAL_OK)
  {
    Error_Handler();
  }
  sMasterConfig.MasterOutputTrigger = TIM_TRGO_RESET;
  sMasterConfig.MasterSlaveMode = TIM_MASTERSLAVEMODE_DISABLE;
  if (HAL_TIMEx_MasterConfigSynchronization(&htim5, &sMasterConfig) != HAL_OK)
  {
    Error_Handler();
  }
  sConfigOC.OCMode = TIM_OCMODE_PWM1;
  sConfigOC.Pulse = 0;
  sConfigOC.OCPolarity = TIM_OCPOLARITY_HIGH;
  sConfigOC.OCFastMode = TIM_OCFAST_DISABLE;
  if (HAL_TIM_PWM_ConfigChannel(&htim5, &sConfigOC, TIM_CHANNEL_1) != HAL_OK)
  {
    Error_Handler();
  }
  if (HAL_TIM_PWM_ConfigChannel(&htim5, &sConfigOC, TIM_CHANNEL_4) != HAL_OK)
  {
    Error_Handler();
  }
  HAL_TIM_MspPostInit(&htim5);

}

static void MX_TIM6_Init(void)
{

  TIM_MasterConfigTypeDef sMasterConfig = {0};

  htim6.Instance = TIM6;
  htim6.Init.Prescaler = 8399;
  htim6.Init.CounterMode = TIM_COUNTERMODE_UP;
  htim6.Init.Period = 1;
  htim6.Init.AutoReloadPreload = TIM_AUTORELOAD_PRELOAD_DISABLE;
  if (HAL_TIM_Base_Init(&htim6) != HAL_OK)
  {
    Error_Handler();
  }
  sMasterConfig.MasterOutputTrigger = TIM_TRGO_UPDATE;
  sMasterConfig.MasterSlaveMode = TIM_MASTERSLAVEMODE_DISABLE;
  if (HAL_TIMEx_MasterConfigSynchronization(&htim6, &sMasterConfig) != HAL_OK)
  {
    Error_Handler();
  }

}

static void MX_TIM9_Init(void)
{

  TIM_OC_InitTypeDef sConfigOC = {0};

  htim9.Instance = TIM9;
  htim9.Init.Prescaler = 0;
  htim9.Init.CounterMode = TIM_COUNTERMODE_UP;
  htim9.Init.Period = 4200;
  htim9.Init.ClockDivision = TIM_CLOCKDIVISION_DIV1;
  htim9.Init.AutoReloadPreload = TIM_AUTORELOAD_PRELOAD_DISABLE;
  if (HAL_TIM_PWM_Init(&htim9) != HAL_OK)
  {
    Error_Handler();
  }
  sConfigOC.OCMode = TIM_OCMODE_PWM1;
  sConfigOC.Pulse = 0;
  sConfigOC.OCPolarity = TIM_OCPOLARITY_HIGH;
  sConfigOC.OCFastMode = TIM_OCFAST_DISABLE;
  if (HAL_TIM_PWM_ConfigChannel(&htim9, &sConfigOC, TIM_CHANNEL_1) != HAL_OK)
  {
    Error_Handler();
  }
  if (HAL_TIM_PWM_ConfigChannel(&htim9, &sConfigOC, TIM_CHANNEL_2) != HAL_OK)
  {
    Error_Handler();
  }
  HAL_TIM_MspPostInit(&htim9);

}

static void MX_TIM10_Init(void)
{

  TIM_OC_InitTypeDef sConfigOC = {0};

  htim10.Instance = TIM10;
  htim10.Init.Prescaler = 0;
  htim10.Init.CounterMode = TIM_COUNTERMODE_UP;
  htim10.Init.Period = 4200;
  htim10.Init.ClockDivision = TIM_CLOCKDIVISION_DIV1;
  htim10.Init.AutoReloadPreload = TIM_AUTORELOAD_PRELOAD_DISABLE;
  if (HAL_TIM_Base_Init(&htim10) != HAL_OK)
  {
    Error_Handler();
  }
  if (HAL_TIM_PWM_Init(&htim10) != HAL_OK)
  {
    Error_Handler();
  }
  sConfigOC.OCMode = TIM_OCMODE_PWM1;
  sConfigOC.Pulse = 0;
  sConfigOC.OCPolarity = TIM_OCPOLARITY_HIGH;
  sConfigOC.OCFastMode = TIM_OCFAST_DISABLE;
  if (HAL_TIM_PWM_ConfigChannel(&htim10, &sConfigOC, TIM_CHANNEL_1) != HAL_OK)
  {
    Error_Handler();
  }
  HAL_TIM_MspPostInit(&htim10);

}

static void MX_TIM11_Init(void)
{

  TIM_OC_InitTypeDef sConfigOC = {0};

  htim11.Instance = TIM11;
  htim11.Init.Prescaler = 0;
  htim11.Init.CounterMode = TIM_COUNTERMODE_UP;
  htim11.Init.Period = 4200;
  htim11.Init.ClockDivision = TIM_CLOCKDIVISION_DIV1;
  htim11.Init.AutoReloadPreload = TIM_AUTORELOAD_PRELOAD_DISABLE;
  if (HAL_TIM_Base_Init(&htim11) != HAL_OK)
  {
    Error_Handler();
  }
  if (HAL_TIM_PWM_Init(&htim11) != HAL_OK)
  {
    Error_Handler();
  }
  sConfigOC.OCMode = TIM_OCMODE_PWM1;
  sConfigOC.Pulse = 0;
  sConfigOC.OCPolarity = TIM_OCPOLARITY_HIGH;
  sConfigOC.OCFastMode = TIM_OCFAST_DISABLE;
  if (HAL_TIM_PWM_ConfigChannel(&htim11, &sConfigOC, TIM_CHANNEL_1) != HAL_OK)
  {
    Error_Handler();
  }
  HAL_TIM_MspPostInit(&htim11);

}

static void MX_TIM12_Init(void)
{

  TIM_OC_InitTypeDef sConfigOC = {0};

  htim12.Instance = TIM12;
  htim12.Init.Prescaler = 0;
  htim12.Init.CounterMode = TIM_COUNTERMODE_UP;
  htim12.Init.Period = 4200;
  htim12.Init.ClockDivision = TIM_CLOCKDIVISION_DIV1;
  htim12.Init.AutoReloadPreload = TIM_AUTORELOAD_PRELOAD_DISABLE;
  if (HAL_TIM_PWM_Init(&htim12) != HAL_OK)
  {
    Error_Handler();
  }
  sConfigOC.OCMode = TIM_OCMODE_PWM1;
  sConfigOC.Pulse = 0;
  sConfigOC.OCPolarity = TIM_OCPOLARITY_HIGH;
  sConfigOC.OCFastMode = TIM_OCFAST_DISABLE;
  if (HAL_TIM_PWM_ConfigChannel(&htim12, &sConfigOC, TIM_CHANNEL_1) != HAL_OK)
  {
    Error_Handler();
  }
  if (HAL_TIM_PWM_ConfigChannel(&htim12, &sConfigOC, TIM_CHANNEL_2) != HAL_OK)
  {
    Error_Handler();
  }
  HAL_TIM_MspPostInit(&htim12);

}

static void MX_USART2_UART_Init(void)
{

  huart2.Instance = USART2;
  huart2.Init.BaudRate = 115200;
  huart2.Init.WordLength = UART_WORDLENGTH_8B;
  huart2.Init.StopBits = UART_STOPBITS_1;
  huart2.Init.Parity = UART_PARITY_NONE;
  huart2.Init.Mode = UART_MODE_TX;
  huart2.Init.HwFlowCtl = UART_HWCONTROL_NONE;
  huart2.Init.OverSampling = UART_OVERSAMPLING_16;
  if (HAL_UART_Init(&huart2) != HAL_OK)
  {
    Error_Handler();
  }

}

static void MX_GPIO_Init(void)
{
  GPIO_InitTypeDef GPIO_InitStruct = {0};

  /* GPIO Ports Clock Enable */
  __HAL_RCC_GPIOE_CLK_ENABLE();
  __HAL_RCC_GPIOC_CLK_ENABLE();
  __HAL_RCC_GPIOH_CLK_ENABLE();
  __HAL_RCC_GPIOA_CLK_ENABLE();
  __HAL_RCC_GPIOB_CLK_ENABLE();
  __HAL_RCC_GPIOD_CLK_ENABLE();

  /*Configure GPIO pin Output Level */
  HAL_GPIO_WritePin(GPIOE, INA3_Pin|INB3_Pin|INA8_Pin|INB8_Pin
                          |INA2_Pin|INA5_Pin|INB2_Pin, GPIO_PIN_RESET);

  /*Configure GPIO pin Output Level */
  HAL_GPIO_WritePin(GPIOC, INA7_Pin|INB7_Pin, GPIO_PIN_RESET);

  /*Configure GPIO pin Output Level */
  HAL_GPIO_WritePin(INA6_GPIO_Port, INA6_Pin, GPIO_PIN_RESET);

  /*Configure GPIO pin Output Level */
  HAL_GPIO_WritePin(GPIOD, INA4_Pin|INB4_Pin|INA1_Pin|INB1_Pin
                          |INB6_Pin|INB5_Pin, GPIO_PIN_RESET);

  /*Configure GPIO pins : INA3_Pin INB3_Pin INA8_Pin INB8_Pin
                           INA2_Pin INA5_Pin INB2_Pin */
  GPIO_InitStruct.Pin = INA3_Pin|INB3_Pin|INA8_Pin|INB8_Pin
                          |INA2_Pin|INA5_Pin|INB2_Pin;
  GPIO_InitStruct.Mode = GPIO_MODE_OUTPUT_PP;
  GPIO_InitStruct.Pull = GPIO_NOPULL;
  GPIO_InitStruct.Speed = GPIO_SPEED_FREQ_LOW;
  HAL_GPIO_Init(GPIOE, &GPIO_InitStruct);

  /*Configure GPIO pins : INA7_Pin INB7_Pin */
  GPIO_InitStruct.Pin = INA7_Pin|INB7_Pin;
  GPIO_InitStruct.Mode = GPIO_MODE_OUTPUT_PP;
  GPIO_InitStruct.Pull = GPIO_NOPULL;
  GPIO_InitStruct.Speed = GPIO_SPEED_FREQ_LOW;
  HAL_GPIO_Init(GPIOC, &GPIO_InitStruct);

  /*Configure GPIO pins : MS7_Pin ENC_B_M3_Pin ENC_B_M5_Pin ENC_B_M2_Pin */
  GPIO_InitStruct.Pin = MS7_Pin|ENC_B_M3_Pin|ENC_B_M5_Pin|ENC_B_M2_Pin;
  GPIO_InitStruct.Mode = GPIO_MODE_INPUT;
  GPIO_InitStruct.Pull = GPIO_PULLUP;
  HAL_GPIO_Init(GPIOC, &GPIO_InitStruct);

  /*Configure GPIO pin : INA6_Pin */
  GPIO_InitStruct.Pin = INA6_Pin;
  GPIO_InitStruct.Mode = GPIO_MODE_OUTPUT_PP;
  GPIO_InitStruct.Pull = GPIO_NOPULL;
  GPIO_InitStruct.Speed = GPIO_SPEED_FREQ_LOW;
  HAL_GPIO_Init(INA6_GPIO_Port, &GPIO_InitStruct);

  /*Configure GPIO pin : RF_WIP_Pin */
  GPIO_InitStruct.Pin = RF_WIP_Pin;
  GPIO_InitStruct.Mode = GPIO_MODE_INPUT;
  GPIO_InitStruct.Pull = GPIO_NOPULL;
  HAL_GPIO_Init(RF_WIP_GPIO_Port, &GPIO_InitStruct);

  /*Configure GPIO pins : MS8_Pin MS3_Pin */
  GPIO_InitStruct.Pin = MS8_Pin|MS3_Pin;
  GPIO_InitStruct.Mode = GPIO_MODE_INPUT;
  GPIO_InitStruct.Pull = GPIO_PULLUP;
  HAL_GPIO_Init(GPIOE, &GPIO_InitStruct);

  /*Configure GPIO pins : MS4_Pin ENC_B_M6_Pin ENC_B_M1_Pin */
  GPIO_InitStruct.Pin = MS4_Pin|ENC_B_M6_Pin|ENC_B_M1_Pin;
  GPIO_InitStruct.Mode = GPIO_MODE_INPUT;
  GPIO_InitStruct.Pull = GPIO_PULLUP;
  HAL_GPIO_Init(GPIOB, &GPIO_InitStruct);

  /*Configure GPIO pins : INA4_Pin INB4_Pin INA1_Pin INB1_Pin
                           INB6_Pin INB5_Pin */
  GPIO_InitStruct.Pin = INA4_Pin|INB4_Pin|INA1_Pin|INB1_Pin
                          |INB6_Pin|INB5_Pin;
  GPIO_InitStruct.Mode = GPIO_MODE_OUTPUT_PP;
  GPIO_InitStruct.Pull = GPIO_NOPULL;
  GPIO_InitStruct.Speed = GPIO_SPEED_FREQ_LOW;
  HAL_GPIO_Init(GPIOD, &GPIO_InitStruct);

  /*Configure GPIO pins : MS2_Pin MS1_Pin MS5_Pin MS6_Pin */
  GPIO_InitStruct.Pin = MS2_Pin|MS1_Pin|MS5_Pin|MS6_Pin;
  GPIO_InitStruct.Mode = GPIO_MODE_INPUT;
  GPIO_InitStruct.Pull = GPIO_PULLUP;
  HAL_GPIO_Init(GPIOD, &GPIO_InitStruct);

  /*Configure GPIO pins : ENC_A_M3_Pin ENC_A_M5_Pin */
  GPIO_InitStruct.Pin = ENC_A_M3_Pin|ENC_A_M5_Pin;
  GPIO_InitStruct.Mode = GPIO_MODE_IT_RISING_FALLING;
  GPIO_InitStruct.Pull = GPIO_PULLUP;
  HAL_GPIO_Init(GPIOD, &GPIO_InitStruct);

  /*Configure GPIO pin : ENC_A_M6_Pin */
  GPIO_InitStruct.Pin = ENC_A_M6_Pin;
  GPIO_InitStruct.Mode = GPIO_MODE_IT_RISING_FALLING;
  GPIO_InitStruct.Pull = GPIO_PULLUP;
  HAL_GPIO_Init(ENC_A_M6_GPIO_Port, &GPIO_InitStruct);

  /*Configure GPIO pin : PA8 */
  GPIO_InitStruct.Pin = GPIO_PIN_8;
  GPIO_InitStruct.Mode = GPIO_MODE_AF_PP;
  GPIO_InitStruct.Pull = GPIO_NOPULL;
  GPIO_InitStruct.Speed = GPIO_SPEED_FREQ_LOW;
  GPIO_InitStruct.Alternate = GPIO_AF0_MCO;
  HAL_GPIO_Init(GPIOA, &GPIO_InitStruct);

  /*Configure GPIO pins : ENC_B_M4_Pin ENC_A_M1_Pin ENC_A_M2_Pin */
  GPIO_InitStruct.Pin = ENC_B_M4_Pin|ENC_A_M1_Pin|ENC_A_M2_Pin;
  GPIO_InitStruct.Mode = GPIO_MODE_IT_RISING_FALLING;
  GPIO_InitStruct.Pull = GPIO_PULLUP;
  HAL_GPIO_Init(GPIOA, &GPIO_InitStruct);

  /*Configure GPIO pin : ENC_A_M4_Pin */
  GPIO_InitStruct.Pin = ENC_A_M4_Pin;
  GPIO_InitStruct.Mode = GPIO_MODE_IT_RISING_FALLING;
  GPIO_InitStruct.Pull = GPIO_PULLUP;
  HAL_GPIO_Init(ENC_A_M4_GPIO_Port, &GPIO_InitStruct);

  /* EXTI interrupt init*/
  HAL_NVIC_SetPriority(EXTI4_IRQn, 5, 0);
  HAL_NVIC_EnableIRQ(EXTI4_IRQn);

  HAL_NVIC_SetPriority(EXTI9_5_IRQn, 5, 0);
  HAL_NVIC_EnableIRQ(EXTI9_5_IRQn);

  HAL_NVIC_SetPriority(EXTI15_10_IRQn, 5, 0);
  HAL_NVIC_EnableIRQ(EXTI15_10_IRQn);

}

/* USER CODE BEGIN 4 */
// void LwIP_DHCP_task() {

//   uint32_t IPaddress;

//   for (;;)
//   {
//     switch (DHCP_state)
//     {
//     case DHCP_START:
//       {
//         dhcp_start(&gnetif);
//         /* IP address should be setted to 0
//            everytime we want to assign a new DHVP address*/
//         IPaddress = 0;
//         DHCP_state = DHCP_WAIT_ADDRESS;
//       }
//       break;

//       case DHCP_WAIT_ADDRESS:
//       {

//         /* Read the new IP address */
//         IPaddress = gnetif.ip_addr.addr;

//         if (IPaddress!=0)
//         {
//           DHCP_state = DHCP_ADDRESS_ASSIGNED;

//           /* Stop DHCP */
//           dhcp_stop(&gnetif);

//         }
//         else
//         {

//         }
//       }
//       break;

//       default: break;
//     }

//     /* wait 250 ms */
//     vTaskDelay(250);
//   }
// }
/* USER CODE END 4 */

void StartDefaultTask(void const * argument)
{
  /* init code for USB_DEVICE */
  MX_USB_DEVICE_Init();
  /* USER CODE BEGIN 5 */
  MX_LWIP_Init();
  Scorbot_MainTask();
  for(;;)
  {
    vTaskDelay(1000);
  }
  /* USER CODE END 5 */
}

void Error_Handler(void)
{
  while(1)
  {
  }
}

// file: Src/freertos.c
/* USER CODE BEGIN Header */
/**
  ******************************************************************************
  * File Name          : freertos.c
  * Description        : Code for freertos applications
  ******************************************************************************
  * @attention
  *
  * Copyright (c) 2025 STMicroelectronics.
  * All rights reserved.
  *
  * This software is licensed under terms that can be found in the LICENSE file
  * in the root directory of this software component.
  * If no LICENSE file comes with this software, it is provided AS-IS.
  *
  ******************************************************************************
  */
/* USER CODE END Header */

#include "FreeRTOS.h"
#include "task.h"
#include "main.h"

/* GetIdleTaskMemory prototype (linked to static allocation support) */
void vApplicationGetIdleTaskMemory( StaticTask_t **ppxIdleTaskTCBBuffer, StackType_t **ppxIdleTaskStackBuffer, uint32_t *pulIdleTaskStackSize );

/* Hook prototypes */
void configureTimerForRunTimeStats(void);
unsigned long getRunTimeCounterValue(void);

/* USER CODE BEGIN 1 */
/* Functions needed when configGENERATE_RUN_TIME_STATS is on */
__weak void configureTimerForRunTimeStats(void)
{

}

__weak unsigned long getRunTimeCounterValue(void)
{
return 0;
}
/* USER CODE END 1 */

/* USER CODE BEGIN GET_IDLE_TASK_MEMORY */
static StaticTask_t xIdleTaskTCBBuffer;
static StackType_t xIdleStack[configMINIMAL_STACK_SIZE];

void vApplicationGetIdleTaskMemory( StaticTask_t **ppxIdleTaskTCBBuffer, StackType_t **ppxIdleTaskStackBuffer, uint32_t *pulIdleTaskStackSize )
{
  *ppxIdleTaskTCBBuffer = &xIdleTaskTCBBuffer;
  *ppxIdleTaskStackBuffer = &xIdleStack[0];
  *pulIdleTaskStackSize = configMINIMAL_STACK_SIZE;
  /* place for user code */
}
/* USER CODE END GET_IDLE_TASK_MEMORY */
